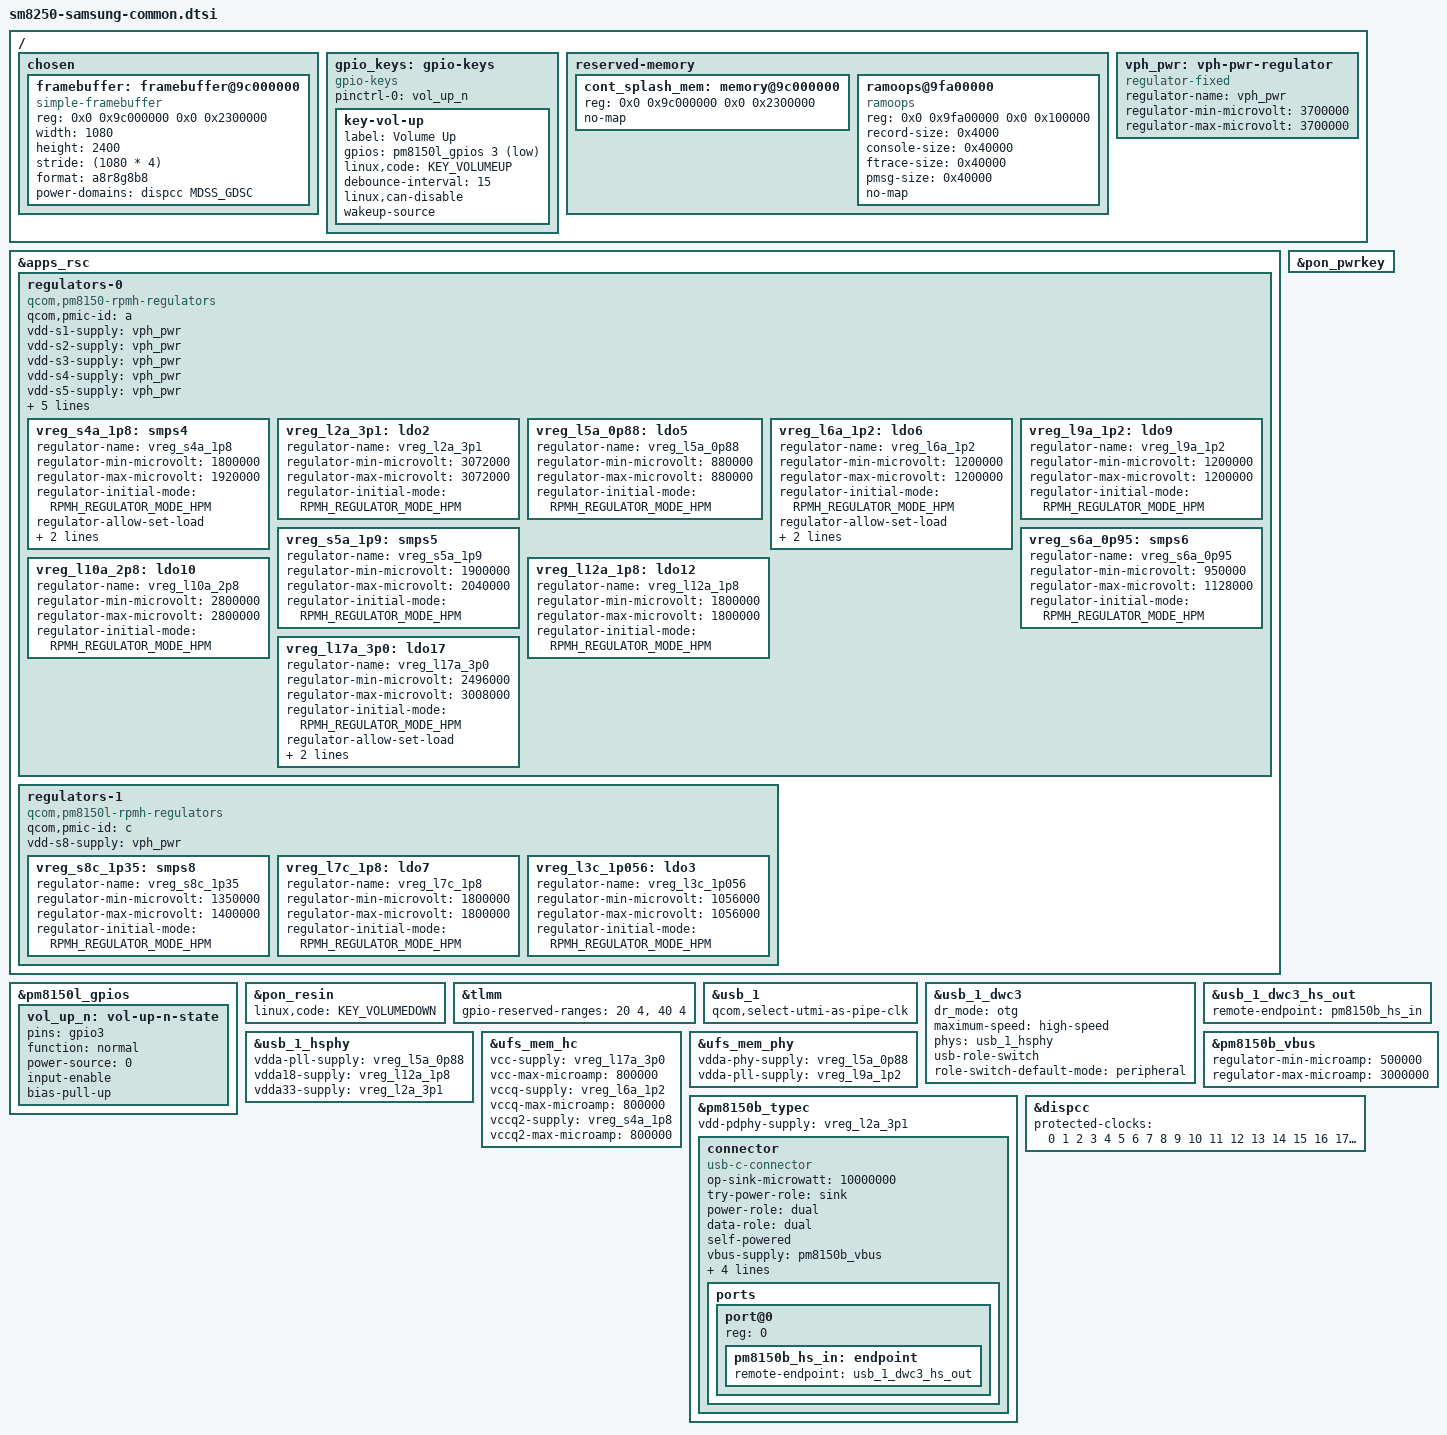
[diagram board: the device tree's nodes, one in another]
// SPDX-License-Identifier: GPL-2.0-only

/dts-v1/;

#include <dt-bindings/regulator/qcom,rpmh-regulator.h>
#include <dt-bindings/usb/pd.h>
#include "sm8250.dtsi"
#include "pm8150.dtsi"
#include "pm8150b.dtsi"
#include "pm8150l.dtsi"

/ {
	chosen {
		#address-cells = <2>;
		#size-cells = <2>;
		ranges;

		framebuffer: framebuffer@9c000000 {
			compatible = "simple-framebuffer";
			reg = <0x0 0x9c000000 0x0 0x2300000>;
			width = <1080>;
			height = <2400>;
			stride = <(1080 * 4)>;
			format = "a8r8g8b8";
			/* Keep MDSS GDSC on: firmware leaves DPU scanning out. */
			power-domains = <&dispcc MDSS_GDSC>;
		};
	};

	gpio_keys: gpio-keys {
		compatible = "gpio-keys";

		pinctrl-names = "default";
		pinctrl-0 = <&vol_up_n>;

		key-vol-up {
			label = "Volume Up";
			/* Wired to pm8150L gpio3 on stock DT, not pm8150. */
			gpios = <&pm8150l_gpios 3 GPIO_ACTIVE_LOW>;
			linux,code = <KEY_VOLUMEUP>;
			debounce-interval = <15>;
			linux,can-disable;
			wakeup-source;
		};
	};

	reserved-memory {
		cont_splash_mem: memory@9c000000 {
			reg = <0x0 0x9c000000 0x0 0x2300000>;
			no-map;
		};

		ramoops@9fa00000 {
			compatible = "ramoops";
			reg = <0x0 0x9fa00000 0x0 0x100000>;
			record-size = <0x4000>;
			console-size = <0x40000>;
			ftrace-size = <0x40000>;
			pmsg-size = <0x40000>;
			no-map;
		};
	};

	vph_pwr: vph-pwr-regulator {
		compatible = "regulator-fixed";
		regulator-name = "vph_pwr";
		regulator-min-microvolt = <3700000>;
		regulator-max-microvolt = <3700000>;
	};
};

&apps_rsc {
	regulators-0 {
		compatible = "qcom,pm8150-rpmh-regulators";
		qcom,pmic-id = "a";

		vdd-s1-supply = <&vph_pwr>;
		vdd-s2-supply = <&vph_pwr>;
		vdd-s3-supply = <&vph_pwr>;
		vdd-s4-supply = <&vph_pwr>;
		vdd-s5-supply = <&vph_pwr>;
		vdd-s6-supply = <&vph_pwr>;
		vdd-s7-supply = <&vph_pwr>;
		vdd-s8-supply = <&vph_pwr>;
		vdd-s9-supply = <&vph_pwr>;
		vdd-s10-supply = <&vph_pwr>;

		vreg_s4a_1p8: smps4 {
			regulator-name = "vreg_s4a_1p8";
			regulator-min-microvolt = <1800000>;
			regulator-max-microvolt = <1920000>;
			regulator-initial-mode = <RPMH_REGULATOR_MODE_HPM>;
			regulator-allow-set-load;
			regulator-allowed-modes = <RPMH_REGULATOR_MODE_LPM
						   RPMH_REGULATOR_MODE_HPM>;
		};

		vreg_l2a_3p1: ldo2 {
			regulator-name = "vreg_l2a_3p1";
			regulator-min-microvolt = <3072000>;
			regulator-max-microvolt = <3072000>;
			regulator-initial-mode = <RPMH_REGULATOR_MODE_HPM>;
		};

		vreg_l5a_0p88: ldo5 {
			regulator-name = "vreg_l5a_0p88";
			regulator-min-microvolt = <880000>;
			regulator-max-microvolt = <880000>;
			regulator-initial-mode = <RPMH_REGULATOR_MODE_HPM>;
		};

		vreg_l6a_1p2: ldo6 {
			regulator-name = "vreg_l6a_1p2";
			regulator-min-microvolt = <1200000>;
			regulator-max-microvolt = <1200000>;
			regulator-initial-mode = <RPMH_REGULATOR_MODE_HPM>;
			regulator-allow-set-load;
			regulator-allowed-modes = <RPMH_REGULATOR_MODE_LPM
						   RPMH_REGULATOR_MODE_HPM>;
		};

		vreg_l9a_1p2: ldo9 {
			regulator-name = "vreg_l9a_1p2";
			regulator-min-microvolt = <1200000>;
			regulator-max-microvolt = <1200000>;
			regulator-initial-mode = <RPMH_REGULATOR_MODE_HPM>;
		};

		/* QCA6390 PMU feeds. */
		vreg_s5a_1p9: smps5 {
			regulator-name = "vreg_s5a_1p9";
			regulator-min-microvolt = <1900000>;
			regulator-max-microvolt = <2040000>;
			regulator-initial-mode = <RPMH_REGULATOR_MODE_HPM>;
		};

		vreg_s6a_0p95: smps6 {
			regulator-name = "vreg_s6a_0p95";
			regulator-min-microvolt = <950000>;
			regulator-max-microvolt = <1128000>;
			regulator-initial-mode = <RPMH_REGULATOR_MODE_HPM>;
		};

		/* Camera AF actuator supply. */
		vreg_l10a_2p8: ldo10 {
			regulator-name = "vreg_l10a_2p8";
			regulator-min-microvolt = <2800000>;
			regulator-max-microvolt = <2800000>;
			regulator-initial-mode = <RPMH_REGULATOR_MODE_HPM>;
		};

		vreg_l12a_1p8: ldo12 {
			regulator-name = "vreg_l12a_1p8";
			regulator-min-microvolt = <1800000>;
			regulator-max-microvolt = <1800000>;
			regulator-initial-mode = <RPMH_REGULATOR_MODE_HPM>;
		};

		vreg_l17a_3p0: ldo17 {
			regulator-name = "vreg_l17a_3p0";
			regulator-min-microvolt = <2496000>;
			regulator-max-microvolt = <3008000>;
			regulator-initial-mode = <RPMH_REGULATOR_MODE_HPM>;
			regulator-allow-set-load;
			regulator-allowed-modes = <RPMH_REGULATOR_MODE_LPM
						   RPMH_REGULATOR_MODE_HPM>;
		};
	};

	/* pm8150l (RPMh id "c"). */
	regulators-1 {
		compatible = "qcom,pm8150l-rpmh-regulators";
		qcom,pmic-id = "c";

		vdd-s8-supply = <&vph_pwr>;

		/* QCA6390 PMU feeds. */
		vreg_s8c_1p35: smps8 {
			regulator-name = "vreg_s8c_1p35";
			regulator-min-microvolt = <1350000>;
			regulator-max-microvolt = <1400000>;
			regulator-initial-mode = <RPMH_REGULATOR_MODE_HPM>;
		};

		/* Camera I/O rail. */
		vreg_l7c_1p8: ldo7 {
			regulator-name = "vreg_l7c_1p8";
			regulator-min-microvolt = <1800000>;
			regulator-max-microvolt = <1800000>;
			regulator-initial-mode = <RPMH_REGULATOR_MODE_HPM>;
		};

		/* Front camera digital core; 1050 mV is off the NLDO grid. */
		vreg_l3c_1p056: ldo3 {
			regulator-name = "vreg_l3c_1p056";
			regulator-min-microvolt = <1056000>;
			regulator-max-microvolt = <1056000>;
			regulator-initial-mode = <RPMH_REGULATOR_MODE_HPM>;
		};
	};
};

&pm8150l_gpios {
	vol_up_n: vol-up-n-state {
		pins = "gpio3";
		function = "normal";
		power-source = <0>;
		input-enable;
		bias-pull-up;
	};
};

&pon_pwrkey {
	status = "okay";
};

&pon_resin {
	linux,code = <KEY_VOLUMEDOWN>;
	status = "okay";
};

&tlmm {
	gpio-reserved-ranges = <20 4>, /* SPI (fingerprint scanner) */
			       <40 4>; /* Unused */
};

&usb_1 {
	/* Limit to USB 2.0 for now */
	qcom,select-utmi-as-pipe-clk;

	status = "okay";
};

&usb_1_dwc3 {
	dr_mode = "otg";
	maximum-speed = "high-speed";
	/* Remove USB3 phy */
	phys = <&usb_1_hsphy>;
	phy-names = "usb2-phy";
	usb-role-switch;
	role-switch-default-mode = "peripheral";
};

&usb_1_dwc3_hs_out {
	remote-endpoint = <&pm8150b_hs_in>;
};

&usb_1_hsphy {
	vdda-pll-supply = <&vreg_l5a_0p88>;
	vdda18-supply = <&vreg_l12a_1p8>;
	vdda33-supply = <&vreg_l2a_3p1>;

	status = "okay";
};

&ufs_mem_hc {
	vcc-supply = <&vreg_l17a_3p0>;
	vcc-max-microamp = <800000>;
	vccq-supply = <&vreg_l6a_1p2>;
	vccq-max-microamp = <800000>;
	vccq2-supply = <&vreg_s4a_1p8>;
	vccq2-max-microamp = <800000>;

	status = "okay";
};

&ufs_mem_phy {
	vdda-phy-supply = <&vreg_l5a_0p88>;
	vdda-pll-supply = <&vreg_l9a_1p2>;

	status = "okay";
};

&pm8150b_vbus {
	regulator-min-microamp = <500000>;
	regulator-max-microamp = <3000000>;
	status = "okay";
};

&pm8150b_typec {
	vdd-pdphy-supply = <&vreg_l2a_3p1>;
	status = "okay";

	connector {
		compatible = "usb-c-connector";

		op-sink-microwatt = <10000000>;
		try-power-role = "sink";
		power-role = "dual";
		data-role = "dual";
		self-powered;

		vbus-supply = <&pm8150b_vbus>;

		source-pdos = <PDO_FIXED(5000, 3000,
					 PDO_FIXED_DUAL_ROLE |
					 PDO_FIXED_USB_COMM |
					 PDO_FIXED_DATA_SWAP)>;

		sink-pdos = <PDO_FIXED(5000, 3000,
				       PDO_FIXED_DUAL_ROLE |
				       PDO_FIXED_USB_COMM |
				       PDO_FIXED_DATA_SWAP)
				       PDO_VAR(5000, 9000, 3000)>;

		ports {
			#address-cells = <1>;
			#size-cells = <0>;

			port@0 {
				reg = <0>;

				pm8150b_hs_in: endpoint {
					remote-endpoint = <&usb_1_dwc3_hs_out>;
				};
			};
		};
	};
};

&dispcc {
	/* Firmware owns the display clocks feeding the live scanout. */
	protected-clocks = <0 1 2 3 4 5 6 7 8 9 10 11 12 13 14 15 16 17 18 19 20 21 22 23 24 25 26 27 28 29 30 31 32 33 34 35 36 37 38 39 40 41 42 43 44 45 46 47 48 49 50 51 52 53 54 55 56 57>;
};
